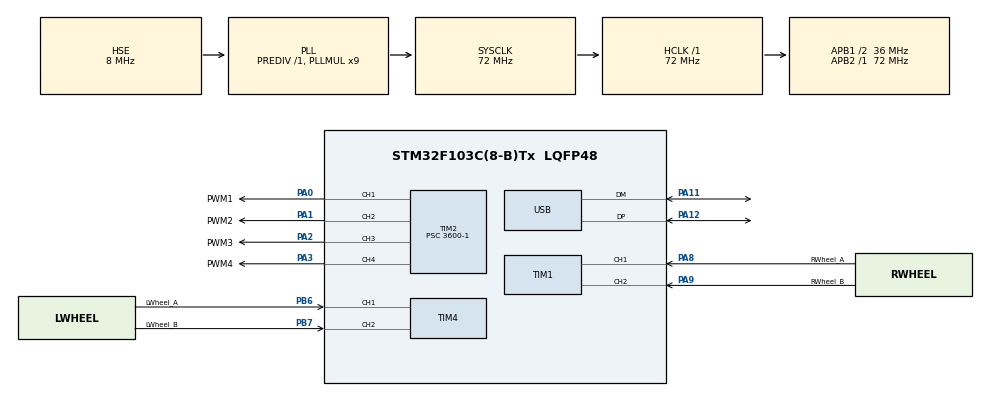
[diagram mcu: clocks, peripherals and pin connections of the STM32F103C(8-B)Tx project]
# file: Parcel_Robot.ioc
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Mcu.Family=STM32F1
Mcu.Name=STM32F103C(8-B)Tx
Mcu.Package=LQFP48
NVIC.PriorityGroup=NVIC_PRIORITYGROUP_4
NVIC.USB_LP_CAN1_RX0_IRQn=true\:0\:0\:false\:false\:true\:false\:true\:true
PA0-WKUP.GPIO_Label=PWM1
PA0-WKUP.Signal=S_TIM2_CH1_ETR
PA1.GPIO_Label=PWM2
PA1.Signal=S_TIM2_CH2
PA11.Mode=Device
PA11.Signal=USB_DM
PA12.Mode=Device
PA12.Signal=USB_DP
PA13.Mode=Serial_Wire
PA13.Signal=SYS_JTMS-SWDIO
PA14.Mode=Serial_Wire
PA14.Signal=SYS_JTCK-SWCLK
PA2.GPIO_Label=PWM3
PA2.Signal=S_TIM2_CH3
PA3.GPIO_Label=PWM4
PA3.Signal=S_TIM2_CH4
PA8.GPIO_Label=RWheel_A
PA8.Signal=S_TIM1_CH1
PA9.GPIO_Label=RWheel_B
PA9.Signal=S_TIM1_CH2
PB6.GPIO_Label=LWheel_A
PB6.Signal=S_TIM4_CH1
PB7.GPIO_Label=LWheel_B
PB7.Signal=S_TIM4_CH2
PD0-OSC_IN.Mode=HSE-External-Oscillator
PD0-OSC_IN.Signal=RCC_OSC_IN
PD1-OSC_OUT.Mode=HSE-External-Oscillator
PD1-OSC_OUT.Signal=RCC_OSC_OUT
ProjectManager.HeapSize=0x200
ProjectManager.StackSize=0x400
ProjectManager.TargetToolchain=STM32CubeIDE
RCC.AHBFreq_Value=72000000
RCC.APB1CLKDivider=RCC_HCLK_DIV2
RCC.APB1Freq_Value=36000000
RCC.APB1TimFreq_Value=72000000
RCC.APB2Freq_Value=72000000
RCC.APB2TimFreq_Value=72000000
RCC.HCLKFreq_Value=72000000
RCC.PLLMUL=RCC_PLL_MUL9
RCC.PLLSourceVirtual=RCC_PLLSOURCE_HSE
RCC.SYSCLKFreq_VALUE=72000000
RCC.SYSCLKSource=RCC_SYSCLKSOURCE_PLLCLK
RCC.USBFreq_Value=48000000
RCC.USBPrescaler=RCC_USBCLKSOURCE_PLL_DIV1_5
SH.S_TIM1_CH1.0=TIM1_CH1,Encoder_Interface
SH.S_TIM1_CH2.0=TIM1_CH2,Encoder_Interface
SH.S_TIM2_CH1_ETR.0=TIM2_CH1,PWM Generation1 CH1
SH.S_TIM2_CH2.0=TIM2_CH2,PWM Generation2 CH2
SH.S_TIM2_CH3.0=TIM2_CH3,PWM Generation3 CH3
SH.S_TIM2_CH4.0=TIM2_CH4,PWM Generation4 CH4
SH.S_TIM4_CH1.0=TIM4_CH1,Encoder_Interface
SH.S_TIM4_CH2.0=TIM4_CH2,Encoder_Interface
TIM1.AutoReloadPreload=TIM_AUTORELOAD_PRELOAD_ENABLE
TIM1.EncoderMode=TIM_ENCODERMODE_TI12
TIM1.IC1Filter=10
TIM1.IC2Filter=10
TIM2.Channel-PWM\ Generation1\ CH1=TIM_CHANNEL_1
TIM2.Channel-PWM\ Generation2\ CH2=TIM_CHANNEL_2
TIM2.Channel-PWM\ Generation3\ CH3=TIM_CHANNEL_3
TIM2.Channel-PWM\ Generation4\ CH4=TIM_CHANNEL_4
TIM2.Prescaler=3600-1
TIM3.Prescaler=36-1
TIM4.EncoderMode=TIM_ENCODERMODE_TI12
TIM4.IC1Filter=10
TIM4.IC2Filter=10
USB_DEVICE.CLASS_NAME_FS=CDC
USB_DEVICE.VirtualMode=Cdc
USB_DEVICE.VirtualModeFS=Cdc_FS
VP_TIM3_VS_ClockSourceINT.Mode=Internal
VP_USB_DEVICE_VS_USB_DEVICE_CDC_FS.Mode=CDC_FS
board=custom

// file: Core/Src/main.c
/* USER CODE BEGIN Header */
/**
  ******************************************************************************
  * @file           : main.c
  * @brief          : Main program body
  ******************************************************************************
  * @attention
  *
  * Copyright (c) 2023 STMicroelectronics.
  * All rights reserved.
  *
  * This software is licensed under terms that can be found in the LICENSE file
  * in the root directory of this software component.
  * If no LICENSE file comes with this software, it is provided AS-IS.
  *
  ******************************************************************************
  */
/* USER CODE END Header */
#include "main.h"
#include "usb_device.h"

/* USER CODE BEGIN Includes */
#include "physical_params.h"
#include "Motor_Control.h"
/* USER CODE END Includes */

TIM_HandleTypeDef htim1;
TIM_HandleTypeDef htim2;
TIM_HandleTypeDef htim3;
TIM_HandleTypeDef htim4;

/* USER CODE BEGIN PV */
TIM_HandleTypeDef* Right_Wheel_Encoder_Tim = &htim1;
TIM_HandleTypeDef* PWM_Timer = &htim2;					// Ch1 = left wheel PWM, ch2 = right wheel PWM
TIM_HandleTypeDef* Micros_Timer = &htim3;
TIM_HandleTypeDef* Left_Wheel_Encoder_Tim = &htim4;
/* USER CODE END PV */

void SystemClock_Config(void);
static void MX_GPIO_Init(void);
static void MX_TIM1_Init(void);
static void MX_TIM2_Init(void);
static void MX_TIM3_Init(void);
static void MX_TIM4_Init(void);

/* USER CODE BEGIN 0 */
uint16_t Micros(TIM_HandleTypeDef* Micros_Timer) {
	return Micros_Timer->Instance->CNT;
}
/* USER CODE END 0 */

int main(void)
{

  /* MCU Configuration--------------------------------------------------------*/

  /* Reset of all peripherals, Initializes the Flash interface and the Systick. */
  HAL_Init();

  /* Configure the system clock */
  SystemClock_Config();

  /* Initialize all configured peripherals */
  MX_GPIO_Init();
  MX_TIM1_Init();
  MX_TIM2_Init();
  MX_TIM3_Init();
  MX_USB_DEVICE_Init();
  MX_TIM4_Init();

  /* Infinite loop */
  while (1)
  {

  }
}

void SystemClock_Config(void)
{
  RCC_OscInitTypeDef RCC_OscInitStruct = {0};
  RCC_ClkInitTypeDef RCC_ClkInitStruct = {0};
  RCC_PeriphCLKInitTypeDef PeriphClkInit = {0};

  /** Initializes the RCC Oscillators according to the specified parameters
  * in the RCC_OscInitTypeDef structure.
  */
  RCC_OscInitStruct.OscillatorType = RCC_OSCILLATORTYPE_HSE;
  RCC_OscInitStruct.HSEState = RCC_HSE_ON;
  RCC_OscInitStruct.HSEPredivValue = RCC_HSE_PREDIV_DIV1;
  RCC_OscInitStruct.HSIState = RCC_HSI_ON;
  RCC_OscInitStruct.PLL.PLLState = RCC_PLL_ON;
  RCC_OscInitStruct.PLL.PLLSource = RCC_PLLSOURCE_HSE;
  RCC_OscInitStruct.PLL.PLLMUL = RCC_PLL_MUL9;
  if (HAL_RCC_OscConfig(&RCC_OscInitStruct) != HAL_OK)
  {
    Error_Handler();
  }

  /** Initializes the CPU, AHB and APB buses clocks
  */
  RCC_ClkInitStruct.ClockType = RCC_CLOCKTYPE_HCLK|RCC_CLOCKTYPE_SYSCLK
                              |RCC_CLOCKTYPE_PCLK1|RCC_CLOCKTYPE_PCLK2;
  RCC_ClkInitStruct.SYSCLKSource = RCC_SYSCLKSOURCE_PLLCLK;
  RCC_ClkInitStruct.AHBCLKDivider = RCC_SYSCLK_DIV1;
  RCC_ClkInitStruct.APB1CLKDivider = RCC_HCLK_DIV2;
  RCC_ClkInitStruct.APB2CLKDivider = RCC_HCLK_DIV1;

  if (HAL_RCC_ClockConfig(&RCC_ClkInitStruct, FLASH_LATENCY_2) != HAL_OK)
  {
    Error_Handler();
  }
  PeriphClkInit.PeriphClockSelection = RCC_PERIPHCLK_USB;
  PeriphClkInit.UsbClockSelection = RCC_USBCLKSOURCE_PLL_DIV1_5;
  if (HAL_RCCEx_PeriphCLKConfig(&PeriphClkInit) != HAL_OK)
  {
    Error_Handler();
  }
}

static void MX_TIM1_Init(void)
{

  TIM_Encoder_InitTypeDef sConfig = {0};
  TIM_MasterConfigTypeDef sMasterConfig = {0};

  htim1.Instance = TIM1;
  htim1.Init.Prescaler = 0;
  htim1.Init.CounterMode = TIM_COUNTERMODE_UP;
  htim1.Init.Period = 65535;
  htim1.Init.ClockDivision = TIM_CLOCKDIVISION_DIV1;
  htim1.Init.RepetitionCounter = 0;
  htim1.Init.AutoReloadPreload = TIM_AUTORELOAD_PRELOAD_ENABLE;
  sConfig.EncoderMode = TIM_ENCODERMODE_TI12;
  sConfig.IC1Polarity = TIM_ICPOLARITY_RISING;
  sConfig.IC1Selection = TIM_ICSELECTION_DIRECTTI;
  sConfig.IC1Prescaler = TIM_ICPSC_DIV1;
  sConfig.IC1Filter = 10;
  sConfig.IC2Polarity = TIM_ICPOLARITY_RISING;
  sConfig.IC2Selection = TIM_ICSELECTION_DIRECTTI;
  sConfig.IC2Prescaler = TIM_ICPSC_DIV1;
  sConfig.IC2Filter = 10;
  if (HAL_TIM_Encoder_Init(&htim1, &sConfig) != HAL_OK)
  {
    Error_Handler();
  }
  sMasterConfig.MasterOutputTrigger = TIM_TRGO_RESET;
  sMasterConfig.MasterSlaveMode = TIM_MASTERSLAVEMODE_DISABLE;
  if (HAL_TIMEx_MasterConfigSynchronization(&htim1, &sMasterConfig) != HAL_OK)
  {
    Error_Handler();
  }

}

static void MX_TIM2_Init(void)
{

  TIM_MasterConfigTypeDef sMasterConfig = {0};
  TIM_OC_InitTypeDef sConfigOC = {0};

  htim2.Instance = TIM2;
  htim2.Init.Prescaler = 3600-1;
  htim2.Init.CounterMode = TIM_COUNTERMODE_UP;
  htim2.Init.Period = 65535;
  htim2.Init.ClockDivision = TIM_CLOCKDIVISION_DIV1;
  htim2.Init.AutoReloadPreload = TIM_AUTORELOAD_PRELOAD_DISABLE;
  if (HAL_TIM_PWM_Init(&htim2) != HAL_OK)
  {
    Error_Handler();
  }
  sMasterConfig.MasterOutputTrigger = TIM_TRGO_RESET;
  sMasterConfig.MasterSlaveMode = TIM_MASTERSLAVEMODE_DISABLE;
  if (HAL_TIMEx_MasterConfigSynchronization(&htim2, &sMasterConfig) != HAL_OK)
  {
    Error_Handler();
  }
  sConfigOC.OCMode = TIM_OCMODE_PWM1;
  sConfigOC.Pulse = 0;
  sConfigOC.OCPolarity = TIM_OCPOLARITY_HIGH;
  sConfigOC.OCFastMode = TIM_OCFAST_DISABLE;
  if (HAL_TIM_PWM_ConfigChannel(&htim2, &sConfigOC, TIM_CHANNEL_1) != HAL_OK)
  {
    Error_Handler();
  }
  if (HAL_TIM_PWM_ConfigChannel(&htim2, &sConfigOC, TIM_CHANNEL_2) != HAL_OK)
  {
    Error_Handler();
  }
  if (HAL_TIM_PWM_ConfigChannel(&htim2, &sConfigOC, TIM_CHANNEL_3) != HAL_OK)
  {
    Error_Handler();
  }
  if (HAL_TIM_PWM_ConfigChannel(&htim2, &sConfigOC, TIM_CHANNEL_4) != HAL_OK)
  {
    Error_Handler();
  }
  HAL_TIM_MspPostInit(&htim2);

}

static void MX_TIM3_Init(void)
{

  TIM_ClockConfigTypeDef sClockSourceConfig = {0};
  TIM_MasterConfigTypeDef sMasterConfig = {0};

  htim3.Instance = TIM3;
  htim3.Init.Prescaler = 36-1;
  htim3.Init.CounterMode = TIM_COUNTERMODE_UP;
  htim3.Init.Period = 65535;
  htim3.Init.ClockDivision = TIM_CLOCKDIVISION_DIV1;
  htim3.Init.AutoReloadPreload = TIM_AUTORELOAD_PRELOAD_DISABLE;
  if (HAL_TIM_Base_Init(&htim3) != HAL_OK)
  {
    Error_Handler();
  }
  sClockSourceConfig.ClockSource = TIM_CLOCKSOURCE_INTERNAL;
  if (HAL_TIM_ConfigClockSource(&htim3, &sClockSourceConfig) != HAL_OK)
  {
    Error_Handler();
  }
  sMasterConfig.MasterOutputTrigger = TIM_TRGO_RESET;
  sMasterConfig.MasterSlaveMode = TIM_MASTERSLAVEMODE_DISABLE;
  if (HAL_TIMEx_MasterConfigSynchronization(&htim3, &sMasterConfig) != HAL_OK)
  {
    Error_Handler();
  }

}

static void MX_TIM4_Init(void)
{

  TIM_Encoder_InitTypeDef sConfig = {0};
  TIM_MasterConfigTypeDef sMasterConfig = {0};

  htim4.Instance = TIM4;
  htim4.Init.Prescaler = 0;
  htim4.Init.CounterMode = TIM_COUNTERMODE_UP;
  htim4.Init.Period = 65535;
  htim4.Init.ClockDivision = TIM_CLOCKDIVISION_DIV1;
  htim4.Init.AutoReloadPreload = TIM_AUTORELOAD_PRELOAD_DISABLE;
  sConfig.EncoderMode = TIM_ENCODERMODE_TI12;
  sConfig.IC1Polarity = TIM_ICPOLARITY_RISING;
  sConfig.IC1Selection = TIM_ICSELECTION_DIRECTTI;
  sConfig.IC1Prescaler = TIM_ICPSC_DIV1;
  sConfig.IC1Filter = 10;
  sConfig.IC2Polarity = TIM_ICPOLARITY_RISING;
  sConfig.IC2Selection = TIM_ICSELECTION_DIRECTTI;
  sConfig.IC2Prescaler = TIM_ICPSC_DIV1;
  sConfig.IC2Filter = 10;
  if (HAL_TIM_Encoder_Init(&htim4, &sConfig) != HAL_OK)
  {
    Error_Handler();
  }
  sMasterConfig.MasterOutputTrigger = TIM_TRGO_RESET;
  sMasterConfig.MasterSlaveMode = TIM_MASTERSLAVEMODE_DISABLE;
  if (HAL_TIMEx_MasterConfigSynchronization(&htim4, &sMasterConfig) != HAL_OK)
  {
    Error_Handler();
  }

}

static void MX_GPIO_Init(void)
{

  /* GPIO Ports Clock Enable */
  __HAL_RCC_GPIOD_CLK_ENABLE();
  __HAL_RCC_GPIOA_CLK_ENABLE();
  __HAL_RCC_GPIOB_CLK_ENABLE();

}

void Error_Handler(void)
{
  __disable_irq();
  while (1)
  {
  }
}
